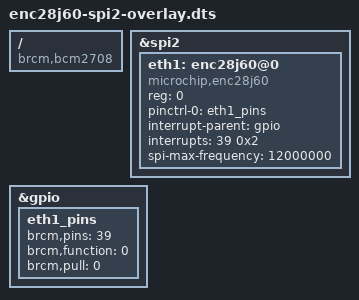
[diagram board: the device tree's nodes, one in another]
// Overlay for the Microchip ENC28J60 Ethernet Controller - SPI2 Compute Module
// Interrupt pin: 39
/dts-v1/;
/plugin/;

/ {
	compatible = "brcm,bcm2708";

	fragment@0 {
		target = <&spi2>;
		__overlay__ {
			/* needed to avoid dtc warning */
			#address-cells = <1>;
			#size-cells = <0>;

			status = "okay";

			eth1: enc28j60@0{
				compatible = "microchip,enc28j60";
				reg = <0>; /* CE0 */
				pinctrl-names = "default";
				pinctrl-0 = <&eth1_pins>;
				interrupt-parent = <&gpio>;
				interrupts = <39 0x2>; /* falling edge */
				spi-max-frequency = <12000000>;
				status = "okay";
			};
		};
	};

	fragment@1 {
		target = <&gpio>;
		__overlay__ {
			eth1_pins: eth1_pins {
				brcm,pins = <39>;
				brcm,function = <0>; /* in */
				brcm,pull = <0>; /* none */
			};
		};
	};

	__overrides__ {
		int_pin = <&eth1>, "interrupts:0",
		          <&eth1_pins>, "brcm,pins:0";
		speed   = <&eth1>, "spi-max-frequency:0";
	};
};
